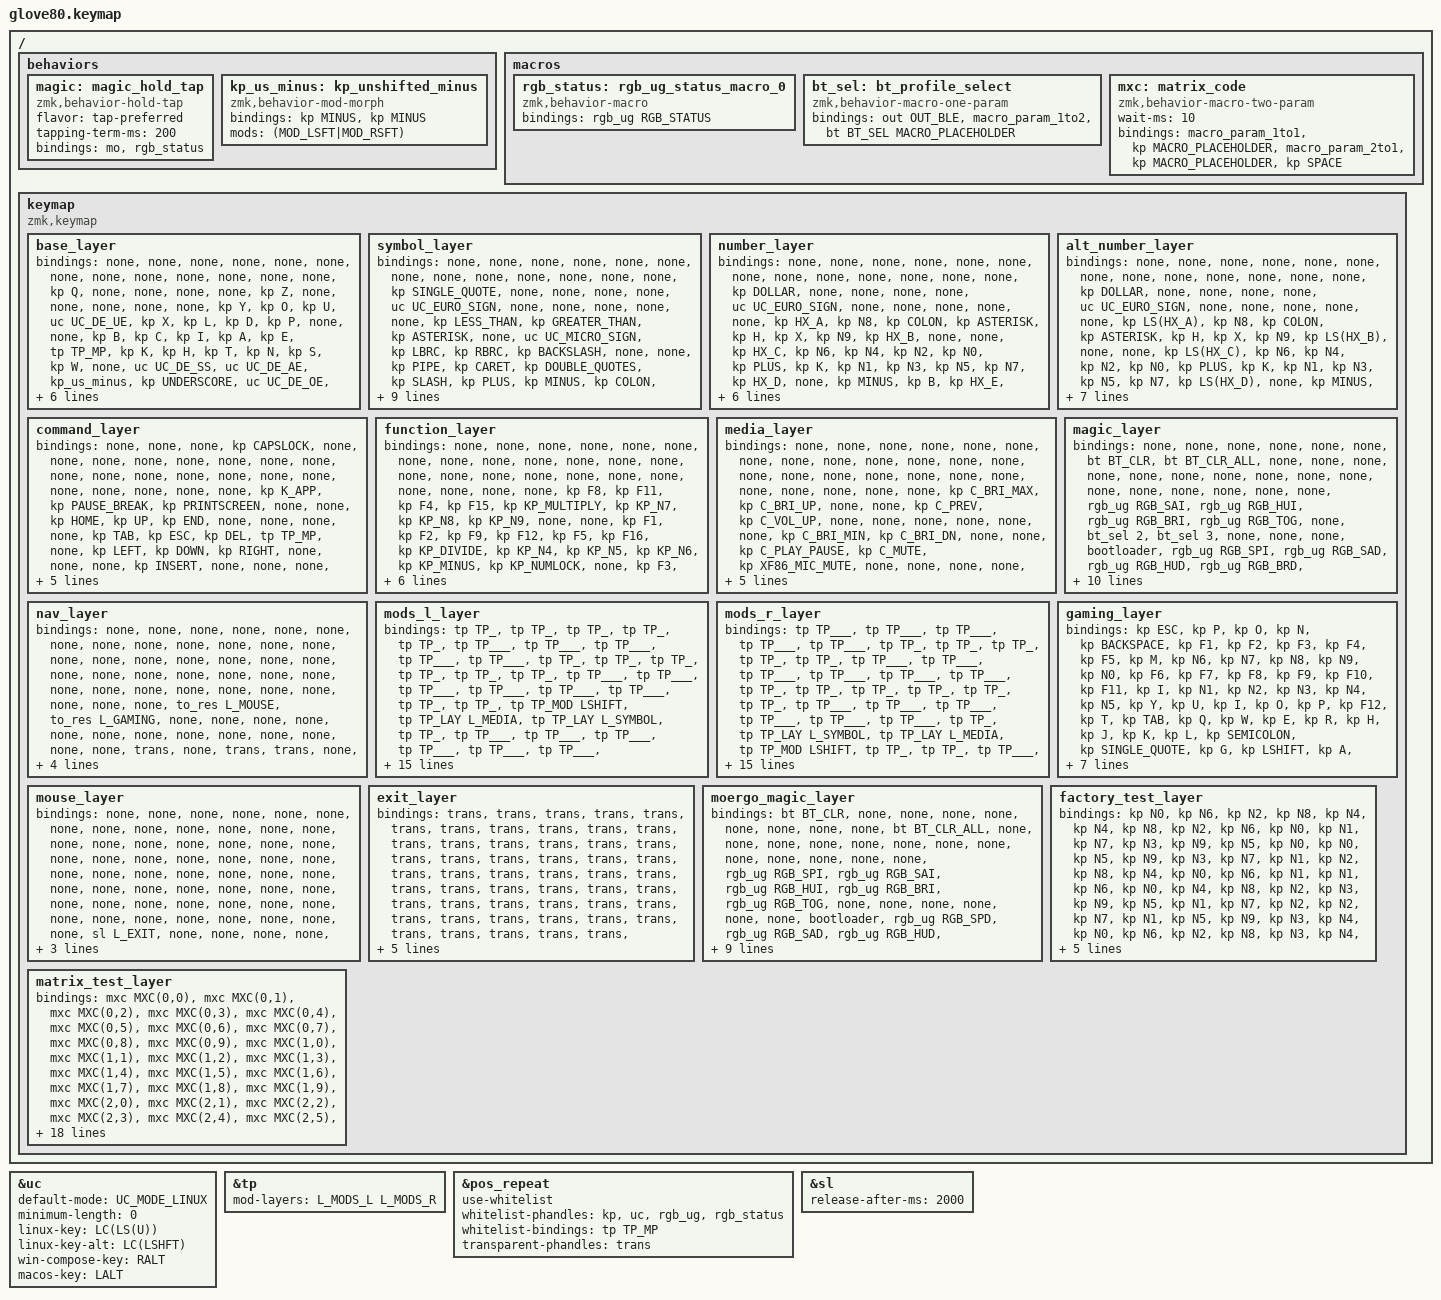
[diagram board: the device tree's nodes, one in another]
/*
 * Copyright (c) 2026 WiggelMc
 *
 * SPDX-License-Identifier: MIT
 */

#include <behaviors.dtsi>
#include <dt-bindings/zmk/keys.h>
#include <dt-bindings/zmk/bt.h>
#include <dt-bindings/zmk/ext_power.h>
#include <dt-bindings/zmk/outputs.h>
#include <dt-bindings/zmk/rgb.h>

#include <behaviors/unicode.dtsi>
#include <zmk-unicode/keys-extra.h>
#include <behaviors/tapithium_mods.dtsi>
#include <tapithium_mods/reset_macros.dtsi>
#include <behaviors/position_repeat.dtsi>

// layers
#define L_BASE 0

#define L_SYMBOL 1
#define L_NUMBER 2
#define L_ALT_NUMBER 3
#define L_COMMAND 4
#define L_FUNCTION 5
#define L_MEDIA 6
#define L_MAGIC 7
#define L_NAV 8

#define L_MODS_L 9
#define L_MODS_R 10

#define L_GAMING 11
#define L_MOUSE 12
#define L_EXIT 13

#define L_MOERGO_MAGIC 14
#define L_FACTORY_TEST 15
#define L_MATRIX_TEST 16

// defines
#define HYPER LC(LS(LG(LALT)))
#define XF86_MIC_MUTE F20
#define MAGIC L_MOERGO_MAGIC 0

#define TP_STICKY_SL TP_STICKY_S L_MODS_L
#define TP_STICKY_SR TP_STICKY_S L_MODS_R
#define TP_ENABLE_SL TP_ENABLE_S L_MODS_L
#define TP_ENABLE_SR TP_ENABLE_S L_MODS_R

#define MXC(a,b) N##a N##b

#define HX_A A
#define HX_B B
#define HX_C C
#define HX_D D
#define HX_E E
#define HX_F F

// config
&uc {
  default-mode = <UC_MODE_LINUX>;
  minimum-length = <0>;
  linux-key = <LC(LS(U))>;
  linux-key-alt = <LC(LSHFT)>;
  win-compose-key = <RALT>;
  macos-key = <LALT>;
};

&tp {
    mod-layers = <L_MODS_L L_MODS_R>;
};

&pos_repeat {
    use-whitelist;
    whitelist-phandles = <&kp &uc &rgb_ug &rgb_status>;
    whitelist-bindings = <&tp TP_MP>;
    transparent-phandles = <&trans>;
    // transparent-bindings = <>;
};

&sl {
    release-after-ms = <2000>;
};


/ {
    behaviors {
        magic: magic_hold_tap {
            compatible = "zmk,behavior-hold-tap";
            #binding-cells = <2>;
            flavor = "tap-preferred";
            tapping-term-ms = <200>;
            bindings = <&mo>, <&rgb_status>;
        };

        kp_us_minus: kp_unshifted_minus {
            compatible = "zmk,behavior-mod-morph";
            #binding-cells = <0>;
            bindings = <&kp MINUS>, <&kp MINUS>;
            mods = <(MOD_LSFT|MOD_RSFT)>;
        };
    };

    macros {
        rgb_status: rgb_ug_status_macro_0 {
            compatible = "zmk,behavior-macro";
            #binding-cells = <0>;
            bindings
                = <&rgb_ug RGB_STATUS>;
        };

        bt_sel: bt_profile_select {
            compatible = "zmk,behavior-macro-one-param";
            #binding-cells = <1>;
            bindings
                = <&out OUT_BLE>,
                  <&macro_param_1to2>,
                  <&bt BT_SEL MACRO_PLACEHOLDER>;
        };

        mxc: matrix_code {
            compatible = "zmk,behavior-macro-two-param";
            #binding-cells = <2>;
            wait-ms = <10>;
            bindings
                = <&macro_param_1to1>,
                  <&kp MACRO_PLACEHOLDER>,
                  <&macro_param_2to1>,
                  <&kp MACRO_PLACEHOLDER>,
                  <&kp SPACE>;
        };
    };

    keymap {
        compatible = "zmk,keymap";

        // Based on Enthium
        base_layer {
            // format: glove80
            bindings = <
                &none         &none         &none         &none         &none                                                                                                                            &none    &none  &none  &none  &none
                &none         &none         &none         &kp Q         &none           &none                                                                                                     &none  &none    &kp Z  &none  &none  &none
                &none         &none         &kp Y         &kp O         &kp U           &uc UC_DE_UE                                                                                              &kp X  &kp L    &kp D  &kp P  &none  &none
                &kp B         &kp C         &kp I         &kp A         &kp E           &tp TP_MP                                                                                                 &kp K  &kp H    &kp T  &kp N  &kp S  &kp W
                &none         &uc UC_DE_SS  &uc UC_DE_AE  &kp_us_minus  &kp UNDERSCORE  &uc UC_DE_OE    &pos_repeat  &kp RETURN            &none      &none  &kp BACKSPACE         &pos_repeat    &kp J  &kp M    &kp G  &kp F  &kp V  &none
                &magic MAGIC  &none         &none         &none         &kp TAB                         &kp SPACE    &tp_res TP_ENABLE_SL  &none      &none  &tp_res TP_ENABLE_SR  &kp R                 &kp ESC  &none  &none  &none  &magic MAGIC
            >;
        };

        symbol_layer {
            // format: glove80
            bindings = <
                &none     &none          &none              &none             &none                                                                                                        &none        &none             &none                &none       &none
                &none     &none          &none              &kp SINGLE_QUOTE  &none           &none                                                                    &none               &none        &uc UC_EURO_SIGN  &none                &none       &none
                &none     &none          &kp LESS_THAN      &kp GREATER_THAN  &kp ASTERISK    &none                                                                    &uc UC_MICRO_SIGN   &kp LBRC     &kp RBRC          &kp BACKSLASH        &none       &none
                &kp PIPE  &kp CARET      &kp DOUBLE_QUOTES  &kp SLASH         &kp PLUS        &kp MINUS                                                                &kp COLON           &kp LPAR     &kp RPAR          &kp COMMA            &kp DOLLAR  &kp EXCLAMATION
                &none     &kp AMPERSAND  &kp LBKT           &kp RBKT          &kp UNDERSCORE  &kp PERCENT    &trans  &trans  &trans      &trans  &trans  &trans        &uc UC_DEGREE_SIGN  &kp EQUAL    &kp GRAVE         &kp SEMICOLON        &kp TILDE   &none
                &trans    &none          &none              &kp HASH          &none                          &trans  &trans  &trans      &trans  &trans  &kp PERIOD                        &kp AT_SIGN  &kp QUESTION      &uc UC_SECTION_SIGN  &none       &trans
            >;
        };

        number_layer {
            // format: glove80
            bindings = <
                &none     &none      &none     &none       &none                                                                                    &none          &none             &none      &none      &none
                &none     &none      &none     &kp DOLLAR  &none      &none                                                                  &none  &none          &uc UC_EURO_SIGN  &none      &none      &none
                &none     &none      &kp HX_A  &kp N8      &kp COLON  &kp ASTERISK                                                           &kp H  &kp X          &kp N9            &kp HX_B   &none      &none
                &kp HX_C  &kp N6     &kp N4    &kp N2      &kp N0     &kp PLUS                                                               &kp K  &kp N1         &kp N3            &kp N5     &kp N7     &kp HX_D
                &none     &kp MINUS  &kp B     &kp HX_E    &kp EQUAL  &kp PERCENT     &trans  &trans  &trans      &trans  &trans  &trans     &kp J  &kp HASH       &kp HX_F          &kp COMMA  &kp SLASH  &none
                &trans    &none      &none     &none       &none                      &trans  &trans  &trans      &trans  &trans  &kp DOT           &kp LESS_THAN  &kp GREATER_THAN  &none      &none      &trans
            >;
        };

        alt_number_layer {
            // format: glove80
            bindings = <
                &none         &none      &none         &none         &none                                                                                    &none          &none             &none         &none      &none
                &none         &none      &none         &kp DOLLAR    &none      &none                                                                  &none  &none          &uc UC_EURO_SIGN  &none         &none      &none
                &none         &none      &kp LS(HX_A)  &kp N8        &kp COLON  &kp ASTERISK                                                           &kp H  &kp X          &kp N9            &kp LS(HX_B)  &none      &none
                &kp LS(HX_C)  &kp N6     &kp N4        &kp N2        &kp N0     &kp PLUS                                                               &kp K  &kp N1         &kp N3            &kp N5        &kp N7     &kp LS(HX_D)
                &none         &kp MINUS  &kp B         &kp LS(HX_E)  &kp EQUAL  &kp PERCENT     &trans  &trans  &trans      &trans  &trans  &trans     &kp J  &kp HASH       &kp LS(HX_F)      &kp COMMA     &kp SLASH  &none
                &trans        &none      &none         &none         &none                      &trans  &trans  &trans      &trans  &trans  &kp DOT           &kp LESS_THAN  &kp GREATER_THAN  &none         &none      &trans
            >;
        };

        command_layer {
            // format: glove80
            bindings = <
                &none   &none       &none      &kp CAPSLOCK     &none                                                                                      &none          &none        &none      &none           &none
                &none   &none       &none      &none            &none            &none                                                              &none  &none          &none        &none      &none           &none
                &none   &none       &kp K_APP  &kp PAUSE_BREAK  &kp PRINTSCREEN  &none                                                              &none  &kp HOME       &kp UP       &kp END    &none           &none
                &none   &none       &kp TAB    &kp ESC          &kp DEL          &tp TP_MP                                                          &none  &kp LEFT       &kp DOWN     &kp RIGHT  &none           &none
                &none   &kp INSERT  &none      &none            &none            &none        &trans  &trans  &trans      &trans  &trans  &trans    &none  &kp PAGE_DOWN  &kp PAGE_UP  &none      &kp SCROLLLOCK  &none
                &trans  &none       &none      &none            &none                         &trans  &trans  &trans      &trans  &trans  &none            &none          &none        &none      &none           &trans
            >;
        };

        function_layer {
            // format: glove80
            bindings = <
                &none   &none   &none    &none    &none                                                                                           &none      &none       &none      &none         &none
                &none   &none   &none    &none    &none   &none                                                                  &none            &none      &none       &none      &none         &none
                &none   &none   &kp F8   &kp F11  &kp F4  &kp F15                                                                &kp KP_MULTIPLY  &kp KP_N7  &kp KP_N8   &kp KP_N9  &none         &none
                &kp F1  &kp F2  &kp F9   &kp F12  &kp F5  &kp F16                                                                &kp KP_DIVIDE    &kp KP_N4  &kp KP_N5   &kp KP_N6  &kp KP_MINUS  &kp KP_NUMLOCK
                &none   &kp F3  &kp F10  &kp F13  &kp F6  &kp F17    &trans  &trans  &trans      &trans  &trans  &trans          &none            &kp KP_N1  &kp KP_N2   &kp KP_N3  &kp KP_PLUS   &none
                &trans  &none   &none    &kp F14  &kp F7             &trans  &trans  &trans      &trans  &trans  &kp KP_ENTER                     &kp KP_N0  &kp KP_DOT  &none      &none         &trans
            >;
        };

        media_layer {
            // format: glove80
            bindings = <
                &none   &none  &none  &none          &none                                                                               &none             &none         &none              &none  &none
                &none   &none  &none  &none          &none         &none                                                          &none  &none             &none         &none              &none  &none
                &none   &none  &none  &kp C_BRI_MAX  &kp C_BRI_UP  &none                                                          &none  &kp C_PREV        &kp C_VOL_UP  &none              &none  &none
                &none   &none  &none  &kp C_BRI_MIN  &kp C_BRI_DN  &none                                                          &none  &kp C_PLAY_PAUSE  &kp C_MUTE    &kp XF86_MIC_MUTE  &none  &none
                &none   &none  &none  &none          &none         &none    &trans  &none   &trans      &trans  &none   &trans    &none  &kp C_NEXT        &kp C_VOL_DN  &none              &none  &none
                &trans  &none  &none  &none          &none                  &none   &trans  &trans      &trans  &trans  &none            &none             &none         &none              &none  &trans
            >;
        };

        magic_layer {
            // format: glove80
            bindings = <
                &none        &none            &none            &none            &none                                                                                                 &none                 &bt BT_CLR              &bt BT_CLR_ALL    &none             &none
                &none        &none            &none            &none            &none            &none                                                                         &none  &none                 &none                   &none             &none             &none
                &none        &none            &rgb_ug RGB_SAI  &rgb_ug RGB_HUI  &rgb_ug RGB_BRI  &rgb_ug RGB_TOG                                                               &none  &bt_sel 2             &bt_sel 3               &none             &none             &none
                &bootloader  &rgb_ug RGB_SPI  &rgb_ug RGB_SAD  &rgb_ug RGB_HUD  &rgb_ug RGB_BRD  &rgb_ug RGB_EFF                                                               &none  &bt_sel 0             &bt_sel 1               &out OUT_USB      &none             &bootloader
                &sys_reset   &rgb_ug RGB_SPD  &none            &none            &none            &none              &trans       &none   &trans      &trans  &none   &trans    &none  &uc UC_SET_LINUX      &uc UC_SET_WIN_COMPOSE  &uc UC_SET_MACOS  &uc UC_SET_EMACS  &sys_reset
                &none        &none            &none            &none            &none                               &rgb_status  &trans  &trans      &trans  &trans  &none            &uc UC_SET_LINUX_ALT  &uc UC_SET_WIN_ALT      &none             &none             &none
            >;
        };

        nav_layer {
            // format: glove80
            bindings = <
                &none   &none  &none  &none            &none                                                                                   &none  &none  &none  &none  &none
                &none   &none  &none  &none            &none             &none                                                          &none  &none  &none  &none  &none  &none
                &none   &none  &none  &none            &none             &none                                                          &none  &none  &none  &none  &none  &none
                &none   &none  &none  &to_res L_MOUSE  &to_res L_GAMING  &none                                                          &none  &none  &none  &none  &none  &none
                &none   &none  &none  &none            &none             &none    &trans  &none   &trans      &trans  &none   &trans    &none  &none  &none  &none  &none  &none
                &trans  &none  &none  &none            &none                      &none   &trans  &trans      &trans  &trans  &none            &none  &none  &none  &none  &trans
            >;
        };

        mods_l_layer {
            // format: glove80
            bindings = <
                &tp TP_             &tp TP_           &tp TP_            &tp TP_                &tp TP_                                                                                                                                     &tp TP___  &tp TP___  &tp TP___  &tp TP___  &tp TP___
                &tp TP_             &tp TP_           &tp TP_            &tp TP_                &tp TP_               &tp TP_                                                                                                    &tp TP___  &tp TP___  &tp TP___  &tp TP___  &tp TP___  &tp TP___
                &tp TP_             &tp TP_           &tp TP_MOD LSHIFT  &tp TP_LAY L_MEDIA     &tp TP_LAY L_SYMBOL   &tp TP_                                                                                                    &tp TP___  &tp TP___  &tp TP___  &tp TP___  &tp TP___  &tp TP___
                &tp TP_LAY L_MAGIC  &tp TP_MOD LGUI   &tp TP_MOD LALT    &tp TP_MOD LCTRL       &tp TP_MOD LSHIFT     &tp TP_LAY L_NUMBER                                                                                        &tp TP___  &tp TP___  &tp TP___  &tp TP___  &tp TP___  &tp TP___
                &tp TP_             &tp TP_LAY L_NAV  &tp TP_MOD LCTRL   &tp TP_LAY L_FUNCTION  &tp TP_LAY L_COMMAND  &tp TP_LAY L_ALT_NUMBER    &tp TP_CANCEL  &tp TP___  &tp TP___      &tp TP___  &tp TP___  &tp TP_CANCEL    &tp TP___  &tp TP___  &tp TP___  &tp TP___  &tp TP___  &tp TP___
                &tp TP_             &tp TP_MOD RGUI   &tp TP_MOD RALT    &tp TP_MOD RCTRL       &tp TP_MOD RSHIFT                                &tp TP___      &trans     &tp TP___      &tp TP___  &trans     &tp TP___                   &tp TP___  &tp TP___  &tp TP___  &tp TP___  &tp TP___
            >;
        };

        // x.split("\n").map(r => {const [s, ...m] = (r+" ").split("&"); return [s, ...m.toReversed()].join("&")}).join("\n");
        mods_r_layer {
            // format: glove80
            bindings = <
                &tp TP___  &tp TP___  &tp TP___  &tp TP___  &tp TP___                                                                                                                        &tp TP_               &tp TP_                &tp TP_            &tp TP_           &tp TP_
                &tp TP___  &tp TP___  &tp TP___  &tp TP___  &tp TP___  &tp TP___                                                                                    &tp TP_                  &tp TP_               &tp TP_                &tp TP_            &tp TP_           &tp TP_
                &tp TP___  &tp TP___  &tp TP___  &tp TP___  &tp TP___  &tp TP___                                                                                    &tp TP_                  &tp TP_LAY L_SYMBOL   &tp TP_LAY L_MEDIA     &tp TP_MOD LSHIFT  &tp TP_           &tp TP_
                &tp TP___  &tp TP___  &tp TP___  &tp TP___  &tp TP___  &tp TP___                                                                                    &tp TP_LAY L_NUMBER      &tp TP_MOD LSHIFT     &tp TP_MOD LCTRL       &tp TP_MOD LALT    &tp TP_MOD LGUI   &tp TP_LAY L_MAGIC
                &tp TP___  &tp TP___  &tp TP___  &tp TP___  &tp TP___  &tp TP___    &tp TP_CANCEL  &tp TP___  &tp TP___      &tp TP___  &tp TP___  &tp TP_CANCEL    &tp TP_LAY L_ALT_NUMBER  &tp TP_LAY L_COMMAND  &tp TP_LAY L_FUNCTION  &tp TP_MOD LCTRL   &tp TP_LAY L_NAV  &tp TP_
                &tp TP___  &tp TP___  &tp TP___  &tp TP___  &tp TP___               &tp TP___      &trans     &tp TP___      &tp TP___  &trans     &tp TP___                                 &tp TP_MOD RSHIFT     &tp TP_MOD RCTRL       &tp TP_MOD RALT    &tp TP_MOD RGUI   &tp TP_
            >;
        };

        // Based on Glorious Engrammer
        gaming_layer {
            // format: glove80
            bindings = <
                &kp ESC  &kp P       &kp O   &kp N   &kp BACKSPACE                                                                                              &kp F1     &kp F2            &kp F3             &kp F4         &kp F5
                &kp M    &kp N6      &kp N7  &kp N8  &kp N9         &kp N0                                                                              &kp F6  &kp F7     &kp F8            &kp F9             &kp F10        &kp F11
                &kp I    &kp N1      &kp N2  &kp N3  &kp N4         &kp N5                                                                              &kp Y   &kp U      &kp I             &kp O              &kp P          &kp F12
                &kp T    &kp TAB     &kp Q   &kp W   &kp E          &kp R                                                                               &kp H   &kp J      &kp K             &kp L              &kp SEMICOLON  &kp SINGLE_QUOTE
                &kp G    &kp LSHIFT  &kp A   &kp S   &kp D          &kp F     &kp LSHIFT  &kp LCTRL  &kp V           &kp UP    &sl L_EXIT  &kp ESC      &kp N   &kp M      &kp COMMA         &kp PERIOD         &kp SLASH      &kp BACKSLASH
                &kp B    &kp LCTRL   &kp Z   &kp X   &kp C                    &kp SPACE   &kp LALT   &kp RETURN      &kp DOWN  &kp LEFT    &kp RIGHT            &kp MINUS  &kp LEFT_BRACKET  &kp RIGHT_BRACKET  &kp EQUAL      &kp GRAVE
            >;
        };

        // TODO: Make Mouse Layer
        mouse_layer {
            // format: glove80
            bindings = <
                &none  &none  &none  &none  &none                                                                       &none  &none  &none  &none  &none
                &none  &none  &none  &none  &none  &none                                                         &none  &none  &none  &none  &none  &none
                &none  &none  &none  &none  &none  &none                                                         &none  &none  &none  &none  &none  &none
                &none  &none  &none  &none  &none  &none                                                         &none  &none  &none  &none  &none  &none
                &none  &none  &none  &none  &none  &none    &none  &none  &none      &none  &sl L_EXIT  &none    &none  &none  &none  &none  &none  &none
                &none  &none  &none  &none  &none           &none  &none  &none      &none  &none       &none           &none  &none  &none  &none  &none
            >;
        };

        exit_layer {
            // format: glove80
            bindings = <
                &trans  &trans  &trans  &trans  &trans                                                                              &trans  &trans  &trans  &trans  &trans
                &trans  &trans  &trans  &trans  &trans  &trans                                                              &trans  &trans  &trans  &trans  &trans  &trans
                &trans  &trans  &trans  &trans  &trans  &trans                                                              &trans  &trans  &trans  &trans  &trans  &trans
                &trans  &trans  &trans  &trans  &trans  &trans                                                              &trans  &trans  &trans  &trans  &trans  &trans
                &trans  &trans  &trans  &trans  &trans  &trans    &to L_BASE  &trans  &trans      &trans  &trans  &trans    &trans  &trans  &trans  &trans  &trans  &trans
                &trans  &trans  &trans  &trans  &trans            &trans      &trans  &trans      &trans  &trans  &trans            &trans  &trans  &trans  &trans  &trans
            >;
        };

        // From Moergo
        moergo_magic_layer {
            // format: glove80
            bindings = <
                &bt BT_CLR   &none            &none            &none            &none                                                                                                     &none                  &none  &none  &none  &bt BT_CLR_ALL
                &none        &none            &none            &none            &none            &none                                                                             &none  &none                  &none  &none  &none  &none
                &none        &rgb_ug RGB_SPI  &rgb_ug RGB_SAI  &rgb_ug RGB_HUI  &rgb_ug RGB_BRI  &rgb_ug RGB_TOG                                                                   &none  &none                  &none  &none  &none  &none
                &bootloader  &rgb_ug RGB_SPD  &rgb_ug RGB_SAD  &rgb_ug RGB_HUD  &rgb_ug RGB_BRD  &rgb_ug RGB_EFF                                                                   &none  &none                  &none  &none  &none  &bootloader
                &sys_reset   &none            &none            &none            &none            &none              &bt_sel 2  &bt_sel 3  &none             &none  &none  &none    &none  &none                  &none  &none  &none  &sys_reset
                &none        &none            &none            &none            &none                               &bt_sel 0  &bt_sel 1  &out OUT_USB      &none  &none  &none           &to_res L_MATRIX_TEST  &none  &none  &none  &to_res L_FACTORY_TEST
            >;
        };

        // From Moergo
        factory_test_layer {
            // format: glove80
            bindings = <
                &kp N0  &kp N6  &kp N2  &kp N8  &kp N4                                                                          &kp N4  &kp N8  &kp N2  &kp N6  &kp N0
                &kp N1  &kp N7  &kp N3  &kp N9  &kp N5  &kp N0                                                          &kp N0  &kp N5  &kp N9  &kp N3  &kp N7  &kp N1
                &kp N2  &kp N8  &kp N4  &kp N0  &kp N6  &kp N1                                                          &kp N1  &kp N6  &kp N0  &kp N4  &kp N8  &kp N2
                &kp N3  &kp N9  &kp N5  &kp N1  &kp N7  &kp N2                                                          &kp N2  &kp N7  &kp N1  &kp N5  &kp N9  &kp N3
                &kp N4  &kp N0  &kp N6  &kp N2  &kp N8  &kp N3    &kp N4  &kp N5  &kp N6      &kp N6  &kp N5  &kp N4    &kp N3  &kp N8  &kp N2  &kp N6  &kp N0  &kp N4
                &kp N5  &kp N1  &kp N7  &kp N3  &kp N9            &kp N7  &kp N8  &kp N9      &kp N9  &kp N8  &kp N7            &kp N9  &kp N3  &kp N7  &kp N1  &kp N5
            >;
        };

        matrix_test_layer {
            // format: glove80
            bindings = <
                &mxc MXC(0,0)  &mxc MXC(0,1)  &mxc MXC(0,2)  &mxc MXC(0,3)  &mxc MXC(0,4)                                                                                                                                  &mxc MXC(0,5)  &mxc MXC(0,6)  &mxc MXC(0,7)  &mxc MXC(0,8)  &mxc MXC(0,9)
                &mxc MXC(1,0)  &mxc MXC(1,1)  &mxc MXC(1,2)  &mxc MXC(1,3)  &mxc MXC(1,4)  &mxc MXC(1,5)                                                                                                    &mxc MXC(1,6)  &mxc MXC(1,7)  &mxc MXC(1,8)  &mxc MXC(1,9)  &mxc MXC(2,0)  &mxc MXC(2,1)
                &mxc MXC(2,2)  &mxc MXC(2,3)  &mxc MXC(2,4)  &mxc MXC(2,5)  &mxc MXC(2,6)  &mxc MXC(2,7)                                                                                                    &mxc MXC(2,8)  &mxc MXC(2,9)  &mxc MXC(3,0)  &mxc MXC(3,1)  &mxc MXC(3,2)  &mxc MXC(3,3)
                &mxc MXC(3,4)  &mxc MXC(3,5)  &mxc MXC(3,6)  &mxc MXC(3,7)  &mxc MXC(3,8)  &mxc MXC(3,9)                                                                                                    &mxc MXC(4,0)  &mxc MXC(4,1)  &mxc MXC(4,2)  &mxc MXC(4,3)  &mxc MXC(4,4)  &mxc MXC(4,5)
                &mxc MXC(4,6)  &mxc MXC(4,7)  &mxc MXC(4,8)  &mxc MXC(4,9)  &mxc MXC(5,0)  &mxc MXC(5,1)    &mxc MXC(5,2)  &mxc MXC(5,3)  &mxc MXC(5,4)      &mxc MXC(5,5)  &mxc MXC(5,6)  &mxc MXC(5,7)    &mxc MXC(5,8)  &mxc MXC(5,9)  &mxc MXC(6,0)  &mxc MXC(6,1)  &mxc MXC(6,2)  &mxc MXC(6,3)
                &mxc MXC(6,4)  &mxc MXC(6,5)  &mxc MXC(6,6)  &mxc MXC(6,7)  &mxc MXC(6,8)                   &mxc MXC(6,9)  &mxc MXC(7,0)  &mxc MXC(7,1)      &mxc MXC(7,2)  &mxc MXC(7,3)  &mxc MXC(7,4)                   &mxc MXC(7,5)  &mxc MXC(7,6)  &mxc MXC(7,7)  &mxc MXC(7,8)  &mxc MXC(7,9)
            >;
        };
    };
};
